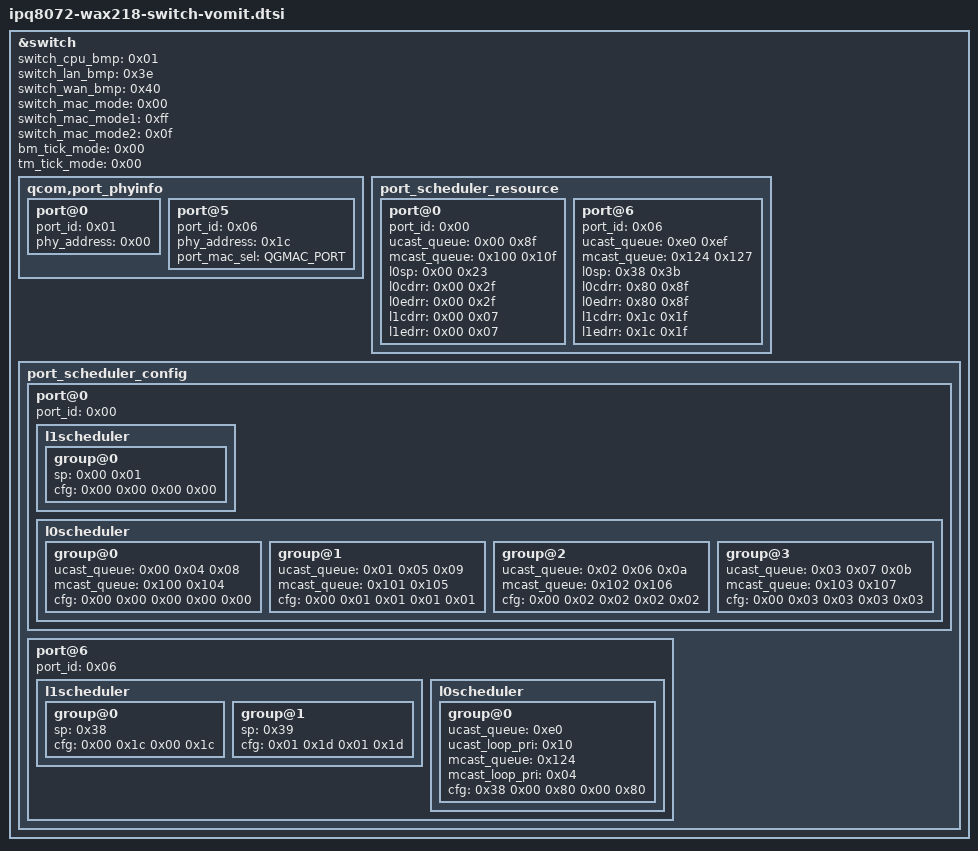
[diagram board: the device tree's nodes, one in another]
&switch {
	status = "okay";

	switch_cpu_bmp = <0x01>;
	switch_lan_bmp = <0x3e>;
	switch_wan_bmp = <0x40>;
	switch_mac_mode = <0x00>;
	switch_mac_mode1 = <0xff>;
	switch_mac_mode2 = <0x0f>;
	bm_tick_mode = <0x00>;
	tm_tick_mode = <0x00>;

	qcom,port_phyinfo {

		port@0 {
			port_id = <0x01>;
			phy_address = <0x00>;
		};

		port@5 {
			port_id = <0x06>;
			phy_address = <0x1c>;
			port_mac_sel = "QGMAC_PORT";
		};
	};

	port_scheduler_resource {

		port@0 {
			port_id = <0x00>;
			ucast_queue = <0x00 0x8f>;
			mcast_queue = <0x100 0x10f>;
			l0sp = <0x00 0x23>;
			l0cdrr = <0x00 0x2f>;
			l0edrr = <0x00 0x2f>;
			l1cdrr = <0x00 0x07>;
			l1edrr = <0x00 0x07>;
		};

		port@6 {
			port_id = <0x06>;
			ucast_queue = <0xe0 0xef>;
			mcast_queue = <0x124 0x127>;
			l0sp = <0x38 0x3b>;
			l0cdrr = <0x80 0x8f>;
			l0edrr = <0x80 0x8f>;
			l1cdrr = <0x1c 0x1f>;
			l1edrr = <0x1c 0x1f>;
		};
	};

	port_scheduler_config {

		port@0 {
			port_id = <0x00>;

			l1scheduler {

				group@0 {
					sp = <0x00 0x01>;
					cfg = <0x00 0x00 0x00 0x00>;
				};
			};

			l0scheduler {

				group@0 {
					ucast_queue = <0x00 0x04 0x08>;
					mcast_queue = <0x100 0x104>;
					cfg = <0x00 0x00 0x00 0x00 0x00>;
				};

				group@1 {
					ucast_queue = <0x01 0x05 0x09>;
					mcast_queue = <0x101 0x105>;
					cfg = <0x00 0x01 0x01 0x01 0x01>;
				};

				group@2 {
					ucast_queue = <0x02 0x06 0x0a>;
					mcast_queue = <0x102 0x106>;
					cfg = <0x00 0x02 0x02 0x02 0x02>;
				};

				group@3 {
					ucast_queue = <0x03 0x07 0x0b>;
					mcast_queue = <0x103 0x107>;
					cfg = <0x00 0x03 0x03 0x03 0x03>;
				};
			};
		};

		port@6 {
			port_id = <0x06>;

			l1scheduler {

				group@0 {
					sp = <0x38>;
					cfg = <0x00 0x1c 0x00 0x1c>;
				};

				group@1 {
					sp = <0x39>;
					cfg = <0x01 0x1d 0x01 0x1d>;
				};
			};

			l0scheduler {

				group@0 {
					ucast_queue = <0xe0>;
					ucast_loop_pri = <0x10>;
					mcast_queue = <0x124>;
					mcast_loop_pri = <0x04>;
					cfg = <0x38 0x00 0x80 0x00 0x80>;
				};
			};
		};
	};
};
